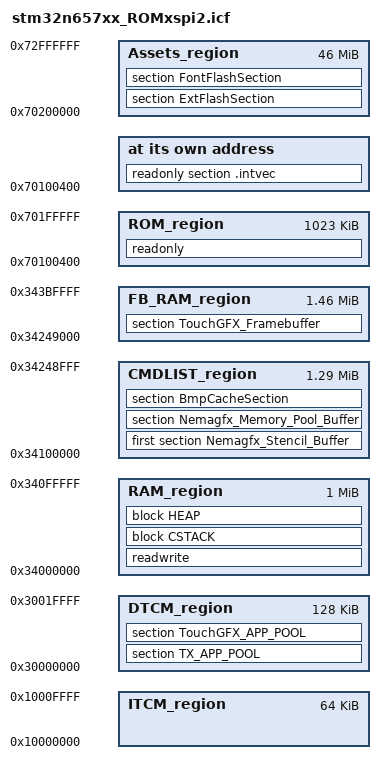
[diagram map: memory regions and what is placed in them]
/*###ICF### Section handled by ICF editor, don't touch! ****/
/*-Editor annotation file-*/
/* IcfEditorFile="$TOOLKIT_DIR$\config\ide\IcfEditor\cortex_v1_0.xml" */
/*-Specials-*/
define symbol __ICFEDIT_intvec_start__ = 0x70100400;
/*-Memory Regions-*/
define symbol __ICFEDIT_region_ROM_start__    = 0x70100400;
define symbol __ICFEDIT_region_ROM_end__      = 0x701FFFFF;
define symbol __ICFEDIT_region_Assets_start__ = 0x70200000;
define symbol __ICFEDIT_region_Assets_end__   = 0x72FFFFFF;
define symbol __ICFEDIT_region_RAM_start__    = 0x34000000;
define symbol __ICFEDIT_region_RAM_end__      = 0x340FFFFF;

define symbol __ICFEDIT_region_CMDLIST_start__ = 0x34100000;
define symbol __ICFEDIT_region_CMDLIST_end__   = 0x34248FFF;
/* define symbol __ICFEDIT_region_CMDLIST_start__ = 0x90000000; */
/* define symbol __ICFEDIT_region_CMDLIST_end__   = 0x90176FFF; */

define symbol __ICFEDIT_region_FB_RAM_start__ = 0x34249000;
define symbol __ICFEDIT_region_FB_RAM_end__   = 0x343BFFFF;

/*-Sizes-*/
define symbol __ICFEDIT_size_cstack__ = 0x1800;
define symbol __ICFEDIT_size_heap__   = 0x1800;
/**** End of ICF editor section. ###ICF###*/

define symbol __region_ITCM_start__  = 0x10000000;
define symbol __region_ITCM_end__    = 0x1000FFFF;
define symbol __region_DTCM_start__  = 0x30000000;
define symbol __region_DTCM_end__    = 0x3001FFFF;

define memory mem with size = 4G;
define region ROM_region      = mem:[from __ICFEDIT_region_ROM_start__ to __ICFEDIT_region_ROM_end__];
define region Assets_region      = mem:[from __ICFEDIT_region_Assets_start__ to __ICFEDIT_region_Assets_end__];
define region RAM_region      = mem:[from __ICFEDIT_region_RAM_start__ to __ICFEDIT_region_RAM_end__];
define region CMDLIST_region      = mem:[from __ICFEDIT_region_CMDLIST_start__ to __ICFEDIT_region_CMDLIST_end__];
define region FB_RAM_region      = mem:[from __ICFEDIT_region_FB_RAM_start__ to __ICFEDIT_region_FB_RAM_end__];
define region ITCM_region     = mem:[from __region_ITCM_start__ to __region_ITCM_end__];
define region DTCM_region     = mem:[from __region_DTCM_start__ to __region_DTCM_end__];

define block CSTACK    with alignment = 8, size = __ICFEDIT_size_cstack__   { };
define block HEAP      with alignment = 8, size = __ICFEDIT_size_heap__     { };

initialize by copy { readwrite };
do not initialize  { section .noinit, section TouchGFX_Framebuffer, section Nemagfx_Stencil_Buffer, section Nemagfx_Memory_Pool_Buffer };

place at address mem:__ICFEDIT_intvec_start__ { readonly section .intvec };

place in ROM_region   { readonly };
place in RAM_region   { readwrite,
                        block CSTACK, block HEAP };
                        
place in CMDLIST_region { first section Nemagfx_Stencil_Buffer
                        , section Nemagfx_Memory_Pool_Buffer,
                        , section BmpCacheSection };

place in FB_RAM_region { section TouchGFX_Framebuffer };

place in Assets_region { section ExtFlashSection,
                         section FontFlashSection};

place in DTCM_region {section TX_APP_POOL, section TouchGFX_APP_POOL};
